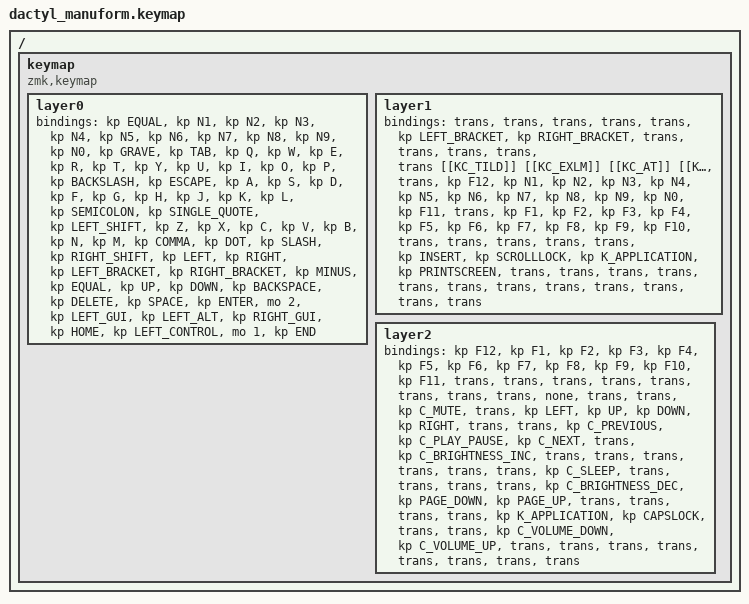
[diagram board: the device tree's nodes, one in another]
// This file was generated from a template. Edit it to match your keyboard.
// See https://zmk.dev/docs/development/hardware-integration/new-shield for more instructions.
#include <behaviors.dtsi>
#include <dt-bindings/zmk/keys.h>
#include <dt-bindings/zmk/bt.h>
#include <dt-bindings/zmk/ext_power.h>

/ {
    keymap {
        compatible = "zmk,keymap";
        layer0 {
            bindings = <
                &kp EQUAL &kp N1 &kp N2 &kp N3 &kp N4 &kp N5 &kp N6 &kp N7 &kp N8 &kp N9 &kp N0 &kp GRAVE &kp TAB &kp Q &kp W &kp E &kp R &kp T &kp Y &kp U &kp I &kp O &kp P &kp BACKSLASH &kp ESCAPE &kp A &kp S &kp D &kp F &kp G &kp H &kp J &kp K &kp L &kp SEMICOLON &kp SINGLE_QUOTE &kp LEFT_SHIFT &kp Z &kp X &kp C &kp V &kp B &kp N &kp M &kp COMMA &kp DOT &kp SLASH &kp RIGHT_SHIFT &kp LEFT &kp RIGHT &kp LEFT_BRACKET &kp RIGHT_BRACKET &kp MINUS &kp EQUAL &kp UP &kp DOWN &kp BACKSPACE &kp DELETE &kp SPACE &kp ENTER &mo 2 &kp LEFT_GUI &kp LEFT_ALT &kp RIGHT_GUI &kp HOME &kp LEFT_CONTROL &mo 1 &kp END
            >;
        };layer1 {
            bindings = <
                &trans &trans &trans &trans &trans &kp LEFT_BRACKET &kp RIGHT_BRACKET &trans &trans &trans &trans &trans [[KC_TILD]] [[KC_EXLM]] [[KC_AT]] [[KC_HASH]] [[KC_DLR]] [[KC_PERC]] [[KC_CIRC]] [[KC_AMPR]] [[KC_ASTR]] [[KC_LPRN]] [[KC_RPRN]] &trans &kp F12 &kp N1 &kp N2 &kp N3 &kp N4 &kp N5 &kp N6 &kp N7 &kp N8 &kp N9 &kp N0 &kp F11 &trans &kp F1 &kp F2 &kp F3 &kp F4 &kp F5 &kp F6 &kp F7 &kp F8 &kp F9 &kp F10 &trans &trans &trans &trans &trans &kp INSERT &kp SCROLLLOCK &kp K_APPLICATION &kp PRINTSCREEN &trans &trans &trans &trans &trans &trans &trans &trans &trans &trans &trans &trans
            >;
        };layer2 {
            bindings = <
                &kp F12 &kp F1 &kp F2 &kp F3 &kp F4 &kp F5 &kp F6 &kp F7 &kp F8 &kp F9 &kp F10 &kp F11 &trans &trans &trans &trans &trans &trans &trans &trans &none &trans &trans &kp C_MUTE &trans &kp LEFT &kp UP &kp DOWN &kp RIGHT &trans &trans &kp C_PREVIOUS &kp C_PLAY_PAUSE &kp C_NEXT &trans &kp C_BRIGHTNESS_INC &trans &trans &trans &trans &trans &trans &kp C_SLEEP &trans &trans &trans &trans &kp C_BRIGHTNESS_DEC &kp PAGE_DOWN &kp PAGE_UP &trans &trans &trans &trans &kp K_APPLICATION &kp CAPSLOCK &trans &trans &kp C_VOLUME_DOWN &kp C_VOLUME_UP &trans &trans &trans &trans &trans &trans &trans &trans
            >;
        };
    };
};

